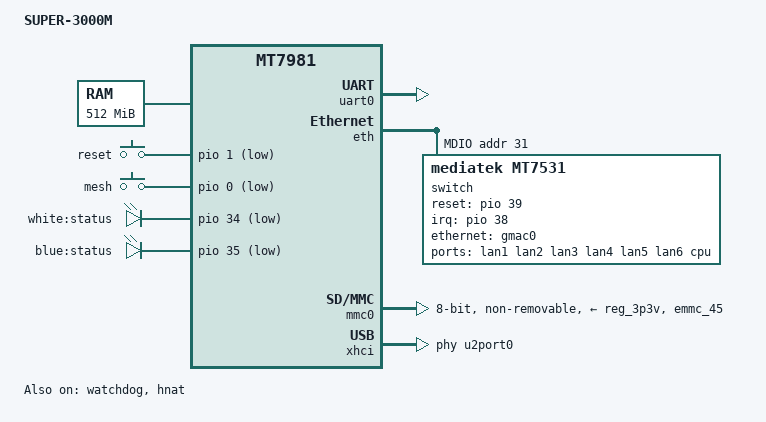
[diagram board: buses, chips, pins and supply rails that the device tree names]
/dts-v1/;
#include <dt-bindings/gpio/gpio.h>
#include <dt-bindings/input/input.h>

#include "mt7981.dtsi"
/ {
    model = "SUPER-3000M";
    compatible = "cxxxfu,super3000m", "mediatek,mt7981";

    chosen {
	    bootargs = "console=ttyS0,115200n1 loglevel=8 \
			earlycon=uart8250,mmio32,0x11002000 \
			root=PARTLABEL=rootfs rootwait rootfstype=squashfs,f2fs";
	};

    aliases {
		led-boot = &led_status_white;
 		led-failsafe = &led_status_white;
 		led-running = &led_status_blue;
 		led-upgrade = &led_status_blue;
	};

	memory {
		reg = <0 0x40000000 0 0x20000000>;
	};

	gpio-keys {

		compatible = "gpio-keys";

		reset {
			label = "reset";
			linux,code = <KEY_RESTART>;
			gpios = <&pio 1 GPIO_ACTIVE_LOW>;
		};

		mesh {
			label = "mesh";
			gpios = <&pio 0 GPIO_ACTIVE_LOW>;
			linux,code = <BTN_9>;
			linux,input-type = <EV_SW>;
		};

	};

    leds {
		compatible = "gpio-leds";

		led_status_white: status_white {
 			label = "white:status";
 			gpios = <&pio 34 GPIO_ACTIVE_LOW>;
 		};

 		led_status_blue: status_blue {
 			label = "blue:status";
 			gpios = <&pio 35 GPIO_ACTIVE_LOW>;
 		};
		
	};
};

&uart0 {
	status = "okay";
};

&watchdog {
	status = "okay";
};

&eth {
	status = "okay";

	gmac0: mac@0 {
		compatible = "mediatek,eth-mac";
		reg = <0>;
		phy-mode = "2500base-x";
		ext-phy-reg = <6>;
		ext-phy-reset-gpios = <&pio 13 GPIO_ACTIVE_LOW>;
		fixed-link {
			speed = <2500>;
			full-duplex;
			pause;
		};
	};

	gmac1: mac@1 {

		/* WAN */
		compatible = "mediatek,eth-mac";
		reg = <1>;
		phy-mode = "2500base-x";
		ext-phy-reg = <7>;
		ext-phy-reset-gpios = <&pio 12 GPIO_ACTIVE_LOW>;
		fixed-link {
			speed = <2500>;
			full-duplex;
			pause;
		};

	};

	mdio: mdio-bus {
		#address-cells = <1>;
		#size-cells = <0>;
    };
};

&mdio{
	switch: switch@1f {
        compatible = "mediatek,mt7531";
        reg = <31>;
	    reset-gpios = <&pio 39 GPIO_ACTIVE_HIGH>;
		interrupt-controller;
		#interrupt-cells = <1>;
		interrupt-parent = <&pio>;
		interrupts = <38 IRQ_TYPE_LEVEL_HIGH>;
	};
};

&switch {
	ports {
		#address-cells = <1>;
		#size-cells = <0>;

		port@0 {
			reg = <0>;
			label = "lan1";
		};

		port@1 {
			reg = <1>;
			label = "lan2";
		};

		port@2 {
			reg = <2>;
			label = "lan3";
		};

		port@3 {
			reg = <3>;
			label = "lan4";
		};

		port@4 {
			reg = <4>;
			label = "lan5";
		};

		port@5 {
			reg = <5>;
			label = "lan6";
			phy-mode = "2500base-x";

			fixed-link {
				speed = <2500>;
				full-duplex;
				pause;
			};
		};
	
		port@6 {
			reg = <6>;
			label = "cpu";
			ethernet = <&gmac0>;
			phy-mode = "2500base-x";

			fixed-link {
				speed = <2500>;
				full-duplex;
				pause;
			};
		};
	};
};



&hnat {
	mtketh-wan = "eth1";
	mtketh-lan = "lan";
	mtketh-max-gmac = <2>;
	ext-devices-prefix = "usb", "wwan";
	status = "okay";
};

&mmc0 {
	bus-width = <8>;
	max-frequency = <52000000>;
	no-sd;
	no-sdio;
	non-removable;
	pinctrl-names = "default", "state_uhs";
	pinctrl-0 = <&mmc0_pins_default>;
	pinctrl-1 = <&mmc0_pins_uhs>;
	vmmc-supply = <&reg_3p3v>;
	non-removable;
	status = "okay";
};

&pio {
	mmc0_pins_default: mmc0-pins-default {
		mux {
			function = "flash";
			groups = "emmc_45";
		};
	};
	mmc0_pins_uhs: mmc0-pins-uhs {
		mux {
			function = "flash";
			groups = "emmc_45";
		};
	};
};

&xhci {
	status = "okay";
	phys = <&u2port0 PHY_TYPE_USB2>;
};



